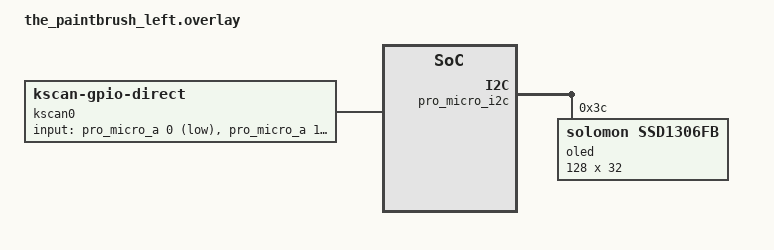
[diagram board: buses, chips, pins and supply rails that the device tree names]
/*
 * Copyright (c) 2021 Mike "KemoNine" Crosson
 * SPDX-License-Identifier: MIT
 *
 * External power is forced ON at boot to keep VCC alive for the OLED.
 * The nice!nano v2 controls VCC via GPIO P0.13 — without this,
 * the OLED gets no power.
 */

#include <dt-bindings/zmk/matrix_transform.h>

/ {
	chosen {
		zmk,kscan = &kscan0;
		zephyr,display = &oled;
	};

	kscan0: kscan_0 {
		compatible = "zmk,kscan-gpio-direct";

		input-gpios
			= <&pro_micro_a 0 (GPIO_ACTIVE_LOW | GPIO_PULL_UP)>
            , <&pro_micro_a 1 (GPIO_ACTIVE_LOW | GPIO_PULL_UP)>
            , <&pro_micro_a 2 (GPIO_ACTIVE_LOW | GPIO_PULL_UP)>
            , <&pro_micro_a 3 (GPIO_ACTIVE_LOW | GPIO_PULL_UP)>
            , <&pro_micro_d 10 (GPIO_ACTIVE_LOW | GPIO_PULL_UP)>
            , <&pro_micro_d 16 (GPIO_ACTIVE_LOW | GPIO_PULL_UP)>
            , <&pro_micro_d 14 (GPIO_ACTIVE_LOW | GPIO_PULL_UP)>
            , <&pro_micro_d 15 (GPIO_ACTIVE_LOW | GPIO_PULL_UP)>
            ;
	};
};

/* Force external power rail ON at boot */
&vdd_env {
	startup-delay-us = <5000>;
	regulator-boot-on;
};

&pro_micro_i2c {
	status = "okay";

	oled: ssd1306@3c {
		compatible = "solomon,ssd1306fb";
		reg = <0x3c>;
		width = <128>;
		height = <32>;
		segment-offset = <0>;
		page-offset = <0>;
		display-offset = <0>;
		multiplex-ratio = <31>;
		segment-remap;
		com-invdir;
		com-sequential;
		inversion-on;
		prechargep = <0x22>;
		ready-time-ms = <128>;
	};
};
